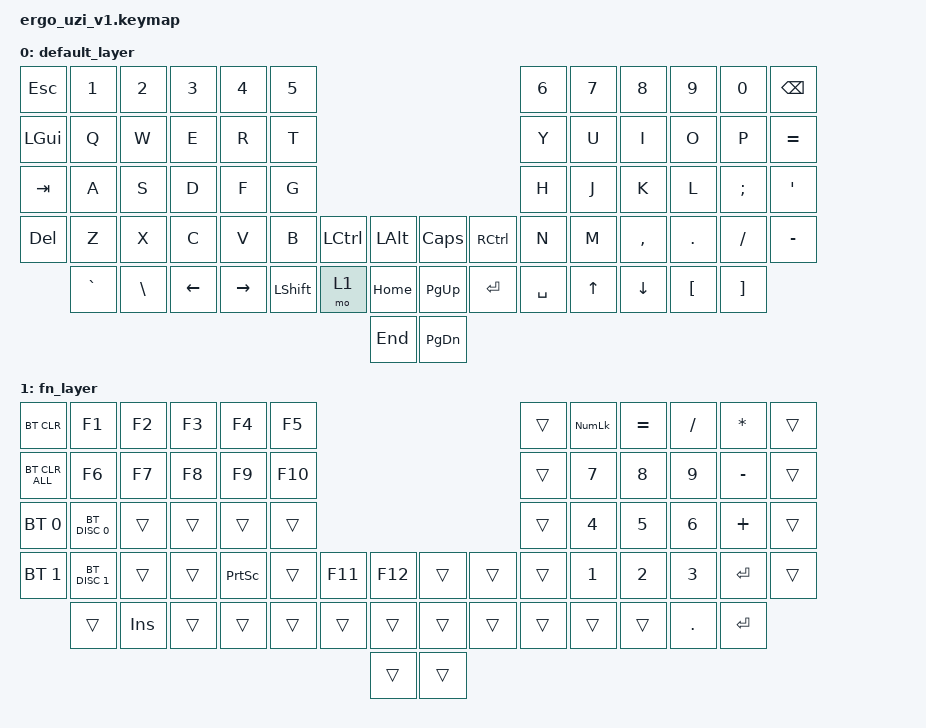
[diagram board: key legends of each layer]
/*
 * Copyright (c) 2021 The ZMK Contributors
 *
 * SPDX-License-Identifier: MIT
 */

#include <behaviors.dtsi>
#include <dt-bindings/zmk/keys.h>
#include <dt-bindings/zmk/bt.h>
#include <dt-bindings/zmk/ext_power.h>
#include <dt-bindings/zmk/outputs.h>

 #define DEFAULT 0
 #define FN  1
 
/* Uncomment this block if using RGB
&led_strip {
    chain-length = <6>;
    // chain-length = <31>; // Uncomment if using both per-key and underglow LEDs
    // chain-length = <25>; // Uncomment if using only per-key LEDs.
};
 */

/ {
       keymap {
              compatible = "zmk,keymap";

              default_layer {
// ---------------------------------------------------------------------------------------------------------------------------------
// | ESC  |  1   |  2   |  3   |  4   |  5   |                                                   |  6   |  7   |  8   |  9   |  0   | BSPC |
// | WIN  |  Q   |  W   |  E   |  R   |  T   |                                                   |  Y   |  U   |  I   |  O   |  P   | EQL  |
// | TAB  |  A   |  S   |  D   |  F   |  G   |                                                   |  H   |  J   |  K   |  L   | SCLN | QUOT |
// | LCTL |  Z   |  X   |  C   |  V   |  B   |      | CTL  | ALT  |         | CAPS | CTL  |      |  N   |  M   | COMM | DOT  | SLSH | MINS |
//        | GRV  | BSLS | LEFT | RGHT |      | SHFT |  FN  | HOME |         | PGUP | ENT  | SPC  |      |  UP  |  DN  | LBKT | RBKT |
//                                                         | END  |         | PGDN |
                     bindings = <
        &kp ESC    &kp N1  &kp N2   &kp N3   &kp N4    &kp N5                                                                    &kp N6    &kp N7    &kp N8    &kp N9     &kp N0    &kp BSPC
        &kp LGUI   &kp Q   &kp W    &kp E    &kp R     &kp T                                                                     &kp Y     &kp U     &kp I     &kp O      &kp P     &kp EQUAL
        &kp TAB    &kp A   &kp S    &kp D    &kp F     &kp G                                                                     &kp H     &kp J     &kp K     &kp L      &kp SEMI  &kp SQT
        &kp DEL    &kp Z   &kp X    &kp C    &kp V     &kp B               &kp LCTRL &kp LALT      &kp CAPS  &kp RCTRL           &kp N     &kp M     &kp COMMA &kp PERIOD &kp SLASH &kp MINUS
                   &kp GRAVE &kp BSLH &kp LEFT &kp RIGHT         &kp LSHFT &mo 1     &kp HOME      &kp PG_UP &kp ENTER &kp SPACE           &kp UP    &kp DOWN  &kp LBKT   &kp RBKT
                                                                                     &kp END       &kp PG_DN
                     >;
              };
              fn_layer {
// ---------------------------------------------------------------------------------------------------------------------------------
// |BT_CLR|  F1  |  F2  |  F3  |  F4  |  F5  |                                                   |      | NLCK |  =   |  /   |  *   |      |
// |      |  F6  |  F7  |  F8  |  F9  |  F10 |                                                   |      |  7   |  8   |  9   |  -   |      |
// |      |      |      |      |      |      |                                                   |      |  4   |  5   |  6   |  +   |      |
// |      |      |      |      |      | PTSC |      |      |      |         |      |      |      |      |  1   |  2   |  3   | ENT  |      |
//        |      | INS  |      |      |      |      |  FN  |      |         |      |      |      |      |      |      |  .   | ENT  |
//                                                         |      |         |      |
                     bindings = <
        &bt BT_CLR &kp F1  &kp F2   &kp F3   &kp F4    &kp F5                                                                    &trans    &kp KP_NUM&kp EQL   &kp SLASH &kp STAR  &trans
        &bt BT_CLR_ALL &kp F6  &kp F7   &kp F8   &kp F9    &kp F10                                                                   &trans    &kp N7    &kp N8    &kp N9    &kp MINUS &trans
        &bt BT_SEL 0 &bt BT_DISC 0  &trans   &trans   &trans    &trans                                                                    &trans    &kp N4    &kp N5    &kp N6    &kp PLUS  &trans
        &bt BT_SEL 1 &bt BT_DISC 1  &trans   &trans   &kp PSCRN &trans              &kp F11   &kp F12       &trans    &trans              &trans    &kp N1    &kp N2    &kp N3    &kp ENTER &trans
                   &trans  &kp INS  &trans   &trans              &trans    &trans    &trans        &trans    &trans    &trans              &trans    &trans    &kp DOT   &kp ENTER
                                                                                     &trans        &trans
                     >;
              };

    };
};
